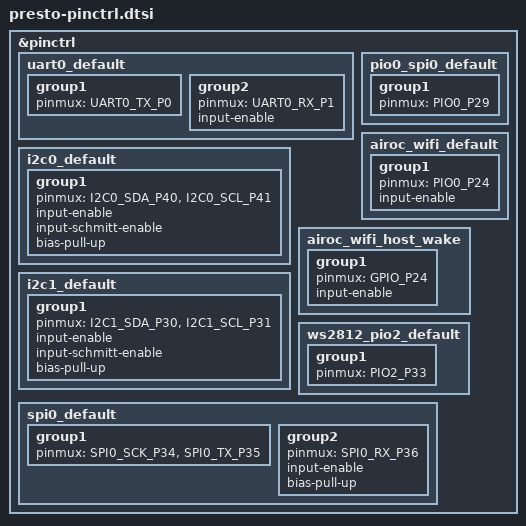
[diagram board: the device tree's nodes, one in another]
/*
 * SPDX-License-Identifier: MIT
 *
 * Pin function selection for the Pimoroni Presto (RP2350B QFN-80).
 *
 * Pin assignments derived from the official Presto schematic and from
 * pimoroni/presto:boards/presto/presto.h.
 */

#include <zephyr/dt-bindings/pinctrl/rpi-pico-rp2350b-pinctrl.h>

&pinctrl {
	/*
	 * UART0 sits on GP0/GP1. The display also uses these pins as
	 * blue data lanes (B7/B6) when the panel is brought up. With the
	 * display node disabled (current state of this port) UART0 is the
	 * console; if the display is ever enabled, the lines collide.
	 */
	uart0_default: uart0_default {
		group1 {
			pinmux = <UART0_TX_P0>;
		};
		group2 {
			pinmux = <UART0_RX_P1>;
			input-enable;
		};
	};

	/* I2C0: Qw/ST connector (SDA=GP40, SCL=GP41).
	 * Qwiic/STEMMA breakouts carry their own pull-ups, but enable the
	 * RP2350 internal pulls too so the bus is usable bare.
	 */
	i2c0_default: i2c0_default {
		group1 {
			pinmux = <I2C0_SDA_P40>, <I2C0_SCL_P41>;
			input-enable;
			input-schmitt-enable;
			bias-pull-up;
		};
	};

	/* I2C1: FT6236 capacitive touch (SDA=GP30, SCL=GP31).
	 * This is an on-board bus with no external pull-ups, so the RP2350
	 * internal pull-ups are required (MicroPython enables them too);
	 * without bias-pull-up every transaction NACKs (-EIO).
	 */
	i2c1_default: i2c1_default {
		group1 {
			pinmux = <I2C1_SDA_P30>, <I2C1_SCL_P31>;
			input-enable;
			input-schmitt-enable;
			bias-pull-up;
		};
	};

	/* PIO0-SPI CLK for the CYW43439 PIO-SPI controller. */
	pio0_spi0_default: pio0_spi0_default {
		group1 {
			pinmux = <PIO0_P29>;
		};
	};

	/* CYW43439 data line is bidirectional and bus-selected via PIO0. */
	airoc_wifi_default: airoc_wifi_default {
		group1 {
			pinmux = <PIO0_P24>;
			input-enable;
		};
	};

	/* Same line in GPIO mode for host-wake IRQ. */
	airoc_wifi_host_wake: airoc_wifi_host_wake {
		group1 {
			pinmux = <GPIO_P24>;
			input-enable;
		};
	};

	/* WS2812 (7x SK6812) chain data on GP33, driven by PIO2 (PIO0 hosts Wi-Fi). */
	ws2812_pio2_default: ws2812_pio2_default {
		group1 {
			pinmux = <PIO2_P33>;
		};
	};

	/*
	 * microSD in SPI mode on the hardware SPI0 controller: SCLK=GP34,
	 * MOSI=GP35 (the card's CMD), MISO=GP36 (the card's DAT0).
	 *
	 * The slot is wired for 4-bit SDIO, and GP34-GP39 land on SPI0 by pure
	 * luck of the RP2350B pin table -- SPI blocks alternate every eight
	 * pins, and GP32-39 is a SPI0 block whose {SCK, TX, RX} fall exactly on
	 * the three lines SPI mode needs. Nothing else on the board wants SPI0:
	 * the display is PIO1, Wi-Fi PIO0 and the LEDs PIO2.
	 *
	 * The card's chip select is DAT3 (GP39), which is deliberately NOT
	 * pinmuxed here. It stays a plain GPIO so the SDHC driver can hold it
	 * low across a whole multi-block command sequence; the PL022's own chip
	 * select deasserts between transfers, which the SD SPI protocol reads as
	 * the end of the command.
	 *
	 * bias-pull-up on MISO because DAT0 floats whenever no card is seated
	 * (and during the card's own power-up), and a floating input reads as a
	 * stream of 0x00 -- which the SD stack cannot tell from a card holding
	 * the line low, so it waits out the full init timeout instead of failing
	 * fast. The pull-up is what makes an empty slot report "no card".
	 */
	spi0_default: spi0_default {
		group1 {
			pinmux = <SPI0_SCK_P34>, <SPI0_TX_P35>;
		};
		group2 {
			pinmux = <SPI0_RX_P36>;
			input-enable;
			bias-pull-up;
		};
	};
};
